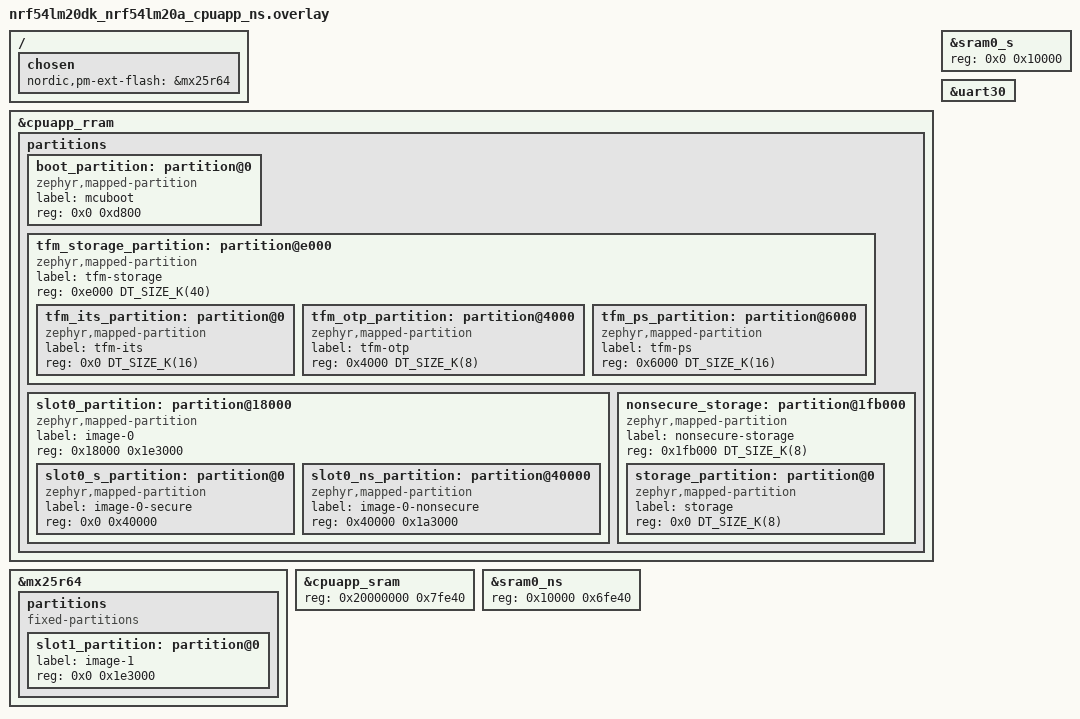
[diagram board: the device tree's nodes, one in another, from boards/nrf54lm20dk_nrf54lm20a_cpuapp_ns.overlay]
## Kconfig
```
#
# Copyright (c) 2022 Nordic Semiconductor ASA
#
# SPDX-License-Identifier: LicenseRef-Nordic-5-Clause
#

menu "Azure IoT Hub sample"

module = AZURE_IOT_HUB_SAMPLE
module-str = Azure IoT Hub sample
source "$(ZEPHYR_BASE)/subsys/logging/Kconfig.template.log_config"

config AZURE_IOT_HUB_SAMPLE_DEVICE_ID_USE_HW_ID
	bool "Use HW ID as device ID"
	select HW_ID_LIBRARY
	help
	  Use the devices's hardware ID as device ID when connecting to Azure IOT Hub

config AZURE_IOT_HUB_SAMPLE_CONNECTION_RETRY_TIMEOUT_SECONDS
	int "Number of seconds between each Azure IoT Hub connection retry"
	default 30
	help
	  If the connection fails, the sample tries to connect again at this interval,
	  or earlier if the network connectivity changes.

endmenu

menu "Zephyr Kernel"
source "Kconfig.zephyr"
endmenu
```

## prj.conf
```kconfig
#
# Copyright (c) 2020 Nordic Semiconductor ASA
#
# SPDX-License-Identifier: LicenseRef-Nordic-5-Clause
#

# General config
CONFIG_REBOOT=y
CONFIG_ASSERT=y

# Logging
CONFIG_LOG=y
CONFIG_LOG_MODE_DEFERRED=y

# Network
CONFIG_NETWORKING=y
CONFIG_NET_NATIVE=y
CONFIG_NET_IPV4=y
CONFIG_NET_CONNECTION_MANAGER=y

# Azure IoT Hub library
CONFIG_MQTT_HELPER_PROVISION_CERTIFICATES=y
CONFIG_AZURE_IOT_HUB=y
CONFIG_AZURE_IOT_HUB_DEVICE_ID="simon-home-nrf7002dk"
# Host name must be configured if DPS is not used
CONFIG_AZURE_IOT_HUB_HOSTNAME="testSthlm.azure-devices.net"
# Change the security tag to the tag where Azure IoT Hub certificates
# are provisioned
CONFIG_MQTT_HELPER_SEC_TAG=10
CONFIG_MQTT_HELPER_STACK_SIZE=8192

# Uncomment to get more verbose logging when debugging
# CONFIG_AZURE_IOT_HUB_LOG_LEVEL_DBG=y

# MQTT - Maximum MQTT keepalive timeout specified by Azure IoT Hub
CONFIG_MQTT_KEEPALIVE=1767

# cJSON
CONFIG_CJSON_LIB=y

# Settings, needed for Azure Device Provisioning Service
CONFIG_FLASH=y
CONFIG_FLASH_MAP=y
CONFIG_FCB=y
CONFIG_SETTINGS=y
CONFIG_SETTINGS_FCB=y
CONFIG_MPU_ALLOW_FLASH_WRITE=y
```

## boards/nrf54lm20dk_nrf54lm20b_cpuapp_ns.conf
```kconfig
#
# Copyright (c) 2026 Nordic Semiconductor ASA
#
# SPDX-License-Identifier: LicenseRef-Nordic-5-Clause
#

# General
CONFIG_POSIX_TIMERS=y
CONFIG_HW_ID_LIBRARY=y
CONFIG_HW_ID_LIBRARY_SOURCE_NET_MAC=y
CONFIG_DK_LIBRARY=y

# Heap and stacks
CONFIG_MAIN_STACK_SIZE=6144
CONFIG_SYSTEM_WORKQUEUE_STACK_SIZE=4096
CONFIG_HEAP_MEM_POOL_SIZE=40144
CONFIG_NRF_WIFI_CTRL_HEAP_SIZE=15000
CONFIG_NRF_WIFI_DATA_HEAP_SIZE=64856
CONFIG_HEAP_MEM_POOL_IGNORE_MIN=y
CONFIG_NET_RX_STACK_SIZE=2048

# Optimize Wi-Fi stack to save some memory
CONFIG_NRF70_RX_NUM_BUFS=16
CONFIG_NRF70_MAX_TX_AGGREGATION=4

# Wi-Fi
CONFIG_WIFI=y
CONFIG_WIFI_NRF70=y
CONFIG_WIFI_NRF70_LOG_LEVEL_ERR=y
CONFIG_WIFI_CREDENTIALS=y
CONFIG_FLASH_PAGE_LAYOUT=y
CONFIG_NET_L2_WIFI_SHELL=y

# Logging: default LOG_PROCESS stack is 768 B; with CONFIG_CBPRINTF_FP_SUPPORT that overflows
# easily and can corrupt state, TF-M secure fault INVEP on the next PSA/crypto call.
CONFIG_LOG_PROCESS_THREAD_STACK_SIZE=4096

# Shell
CONFIG_SHELL=y
CONFIG_SHELL_STACK_SIZE=6144

# WPA
CONFIG_WIFI_NM_WPA_SUPPLICANT=y
CONFIG_WIFI_NM_WPA_SUPPLICANT_LOG_LEVEL_ERR=y

# Zephyr NET Connection Manager Connectivity layer.
CONFIG_L2_WIFI_CONNECTIVITY=y
CONFIG_L2_WIFI_CONNECTIVITY_AUTO_CONNECT=n
CONFIG_L2_WIFI_CONNECTIVITY_AUTO_DOWN=n

# DNS
CONFIG_DNS_RESOLVER=y
CONFIG_NET_SOCKETS_DNS_TIMEOUT=30000

# NET sockets
CONFIG_NET_SOCKETS=y
CONFIG_NET_L2_ETHERNET=y
CONFIG_NET_TCP=y
CONFIG_NET_UDP=y
CONFIG_NET_SOCKETS_OFFLOAD=n
CONFIG_NET_DHCPV4=y
CONFIG_NET_CONTEXT_SNDTIMEO=y
CONFIG_NET_CONTEXT_RCVTIMEO=y

# TLS networking
CONFIG_NET_SOCKETS_SOCKOPT_TLS=y
CONFIG_NET_SOCKETS_ENABLE_DTLS=n
CONFIG_NET_SOCKETS_TLS_MAX_CONTEXTS=2

# mbedTLS
CONFIG_MBEDTLS=y
CONFIG_MBEDTLS_ENABLE_HEAP=y
CONFIG_MBEDTLS_HEAP_SIZE=81920
CONFIG_MBEDTLS_DECLARE_PRIVATE_IDENTIFIERS=y
CONFIG_MBEDTLS_MD_C=y
CONFIG_MBEDTLS_HMAC_DRBG_C=y
CONFIG_MBEDTLS_SHA256_C=y
CONFIG_MBEDTLS_ECP_C=y
CONFIG_MBEDTLS_CTR_DRBG_C=y
CONFIG_MBEDTLS_AES_C=y
CONFIG_MBEDTLS_ENTROPY_C=y
CONFIG_MBEDTLS_RSA_C=y
CONFIG_PSA_WANT_KEY_TYPE_RSA_KEY_PAIR_IMPORT=y
CONFIG_PSA_WANT_KEY_TYPE_RSA_KEY_PAIR_EXPORT=y
CONFIG_PSA_WANT_KEY_TYPE_RSA_KEY_PAIR_GENERATE=y
CONFIG_MBEDTLS_SSL_SERVER_NAME_INDICATION=y
# Set MPI (Multiple Precision Integer) size limit to 512 bytes for handling of 4 kb certificates
# in cryptographic operations.
CONFIG_MBEDTLS_MPI_MAX_SIZE=512
# ECDH/ECDSA are needed for TLS handshake
CONFIG_PSA_WANT_ALG_ECDH=y
CONFIG_PSA_WANT_ALG_ECDSA=y
# CRACEN auto-enables CHACHA20_POLY1305 and certain ECC algorithms. Clients
# pick these ciphers; psa_import_key then fails unless the matching key types
# and curves are explicitly declared here.
CONFIG_PSA_WANT_ECC_SECP_R1_256=y
CONFIG_PSA_WANT_ECC_SECP_R1_384=y
CONFIG_PSA_WANT_ALG_ECDSA_ANY=y
CONFIG_PSA_WANT_KEY_TYPE_CHACHA20=y

# TF-M PSA IPC scratch buffer; inputs+outputs of a single PSA call are copied through it.
# 36864 = 2 * MBEDTLS_SSL_MAX_CONTENT_LEN (16384) + overhead, covering the largest
# in/out buffers seen during the TLS handshake via CRACEN. Values below ~16384 cause
# psa_* calls to fail (ECONNABORTED) during the handshake.
#CONFIG_TFM_CRYPTO_IOVEC_BUFFER_SIZE=36864

# FOTA
CONFIG_AZURE_FOTA=y
CONFIG_AZURE_FOTA_APP_VERSION_AUTO=n
CONFIG_AZURE_FOTA_TLS=y
# Change the security tag to the tag where the certificates are provisioned
# for the server where the FOTA image is hosted
CONFIG_AZURE_FOTA_SEC_TAG=11
CONFIG_BOOTLOADER_MCUBOOT=y
CONFIG_FOTA_DOWNLOAD=y
CONFIG_DFU_TARGET=y
# Not compatible with TF-M NS RAM layout (sysbuild clears this for NS anyway).
CONFIG_MCUBOOT_USE_ALL_AVAILABLE_RAM=n
CONFIG_MCUBOOT_IMG_MANAGER=y
CONFIG_IMG_MANAGER=y
CONFIG_STREAM_FLASH=y
CONFIG_IMG_ERASE_PROGRESSIVELY=y
CONFIG_DOWNLOADER=y
CONFIG_DOWNLOADER_STACK_SIZE=4096

# Enable external flash to host MCUBoot secondary partition
CONFIG_SPI=y
CONFIG_SPI_NOR=y
CONFIG_SPI_NOR_SFDP_DEVICETREE=y

# TLS credentials
CONFIG_TLS_CREDENTIALS_BACKEND_PROTECTED_STORAGE=y

# Configure TF-M
CONFIG_TFM_PROFILE_TYPE_NOT_SET=y
# TF-M and nRF7002EB2 shield use the same UART30. TF-M assigns UART30 to secure environment, which
# causes BusFault when app tries to access it. Disabling logging in TF-M prevent it using UART30.
CONFIG_TFM_LOG_LEVEL_SILENCE=y

# Enable LTO to save flash memory
CONFIG_LTO=y
CONFIG_ISR_TABLES_LOCAL_DECLARATION=y

# Floating-point printf support
CONFIG_CBPRINTF_FP_SUPPORT=y
```

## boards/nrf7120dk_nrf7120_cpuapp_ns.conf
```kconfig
#
# Copyright (c) 2026 Nordic Semiconductor ASA
#
# SPDX-License-Identifier: LicenseRef-Nordic-5-Clause
#

# General
CONFIG_POSIX_TIMERS=y
CONFIG_HW_ID_LIBRARY=y
CONFIG_HW_ID_LIBRARY_SOURCE_NET_MAC=y
CONFIG_DK_LIBRARY=y

# Wi-Fi
CONFIG_WIFI=y
CONFIG_WIFI_NRF71=y
CONFIG_WIFI_CREDENTIALS=y
# Needed for Wi-Fi credentials
CONFIG_FLASH=y
CONFIG_FLASH_PAGE_LAYOUT=y
CONFIG_ZMS=y
CONFIG_SETTINGS=y

# Shell
CONFIG_SHELL=y
CONFIG_SHELL_STACK_SIZE=6144
CONFIG_NET_L2_WIFI_SHELL=y

# WPA
CONFIG_WIFI_NM_WPA_SUPPLICANT=y
CONFIG_WIFI_NM_WPA_SUPPLICANT_LOG_LEVEL_ERR=y

# Zephyr NET Connection Manager Connectivity layer.
CONFIG_L2_WIFI_CONNECTIVITY=y
CONFIG_L2_WIFI_CONNECTIVITY_AUTO_CONNECT=n
CONFIG_L2_WIFI_CONNECTIVITY_AUTO_DOWN=n

# DNS
CONFIG_DNS_RESOLVER=y
CONFIG_NET_SOCKETS_DNS_TIMEOUT=30000

# NET sockets
CONFIG_NET_SOCKETS=y
CONFIG_NET_L2_ETHERNET=y
CONFIG_NET_TCP=y
CONFIG_NET_UDP=y
CONFIG_NET_SOCKETS_OFFLOAD=n
CONFIG_NET_DHCPV4=y
CONFIG_NET_CONTEXT_SNDTIMEO=y
CONFIG_NET_CONTEXT_RCVTIMEO=y

# TLS networking
CONFIG_NET_SOCKETS_SOCKOPT_TLS=y
CONFIG_NET_SOCKETS_ENABLE_DTLS=n
CONFIG_NET_SOCKETS_TLS_MAX_CONTEXTS=2

# mbedTLS
CONFIG_MBEDTLS=y
CONFIG_MBEDTLS_ENABLE_HEAP=y
CONFIG_MBEDTLS_HEAP_SIZE=81920
CONFIG_MBEDTLS_DECLARE_PRIVATE_IDENTIFIERS=y
CONFIG_MBEDTLS_MD_C=y
CONFIG_MBEDTLS_HMAC_DRBG_C=y
CONFIG_MBEDTLS_SHA256_C=y
CONFIG_MBEDTLS_ECP_C=y
CONFIG_MBEDTLS_CTR_DRBG_C=y
CONFIG_MBEDTLS_AES_C=y
CONFIG_MBEDTLS_ENTROPY_C=y
CONFIG_MBEDTLS_RSA_C=y
CONFIG_PSA_WANT_KEY_TYPE_RSA_KEY_PAIR_IMPORT=y
CONFIG_PSA_WANT_KEY_TYPE_RSA_KEY_PAIR_EXPORT=y
CONFIG_PSA_WANT_KEY_TYPE_RSA_KEY_PAIR_GENERATE=y
CONFIG_MBEDTLS_SSL_SERVER_NAME_INDICATION=y
# Set MPI (Multiple Precision Integer) size limit to 512 bytes for handling of 4 kb certificates
# in cryptographic operations.
CONFIG_MBEDTLS_MPI_MAX_SIZE=512
# ECDH/ECDSA are needed for TLS handshake
CONFIG_PSA_WANT_ALG_ECDH=y
CONFIG_PSA_WANT_ALG_ECDSA=y

# HOSTAP_CRYPTO_ALT_PSA (default) force-selects MBEDTLS_USE_PSA_CRYPTO, which
# routes mbedTLS TLS/X.509 operations through PSA via TF-M IPC. This currently
# fails with MBEDTLS_ERR_SSL_HW_ACCEL_FAILED during the TLS handshake on TF-M
# NS builds. The legacy PSA backend does not force MBEDTLS_USE_PSA_CRYPTO, so
# mbedTLS uses its built-in crypto for TLS while WPA supplicant still uses PSA.
CONFIG_HOSTAP_CRYPTO_ALT_LEGACY_PSA=y

# FOTA
CONFIG_AZURE_FOTA=y
CONFIG_AZURE_FOTA_APP_VERSION_AUTO=n
CONFIG_AZURE_FOTA_TLS=y
# Change the security tag to the tag where the certificates are provisioned
# for the server where the FOTA image is hosted
CONFIG_AZURE_FOTA_SEC_TAG=11
CONFIG_BOOTLOADER_MCUBOOT=y
CONFIG_FOTA_DOWNLOAD=y
CONFIG_DFU_TARGET=y

# TLS credentials
CONFIG_TLS_CREDENTIALS_BACKEND_PROTECTED_STORAGE=y

# Enable LTO to save flash memory
CONFIG_LTO=y
CONFIG_ISR_TABLES_LOCAL_DECLARATION=y

# Floating-point printf support
CONFIG_CBPRINTF_FP_SUPPORT=y

# Optimize Wi-Fi stack to save some memory
CONFIG_HEAP_MEM_POOL_SIZE=40144
CONFIG_NRF_WIFI_CTRL_HEAP_SIZE=20000
CONFIG_NRF_WIFI_DATA_HEAP_SIZE=59856
```

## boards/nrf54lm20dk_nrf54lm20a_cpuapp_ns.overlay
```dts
/*
 * Copyright (c) 2026 Nordic Semiconductor ASA
 *
 * SPDX-License-Identifier: LicenseRef-Nordic-5-Clause
 */

/ {
	/* Configure partition manager to use mx25r64 as the external flash */
	chosen {
		nordic,pm-ext-flash = &mx25r64;
	};
};

/delete-node/ &slot0_s_partition;
/delete-node/ &tfm_ps_partition;
/delete-node/ &tfm_its_partition;
/delete-node/ &tfm_otp_partition;
/delete-node/ &slot0_ns_partition;
/delete-node/ &storage_partition;

&cpuapp_rram {
	partitions {
		boot_partition: partition@0 {
			compatible = "zephyr,mapped-partition";
			label = "mcuboot";
			reg = <0x0 0xd800>;
		};

		tfm_storage_partition: partition@e000 {
			compatible = "zephyr,mapped-partition";
			label = "tfm-storage";
			reg = <0xe000 DT_SIZE_K(40)>;
			ranges = <0x0 0xe000 DT_SIZE_K(40)>;
			#address-cells = <1>;
			#size-cells = <1>;

			tfm_its_partition: partition@0 {
				compatible = "zephyr,mapped-partition";
				label = "tfm-its";
				reg = <0x0 DT_SIZE_K(16)>;
			};

			tfm_otp_partition: partition@4000 {
				compatible = "zephyr,mapped-partition";
				label = "tfm-otp";
				reg = <0x4000 DT_SIZE_K(8)>;
			};

			tfm_ps_partition: partition@6000 {
				compatible = "zephyr,mapped-partition";
				label = "tfm-ps";
				reg = <0x6000 DT_SIZE_K(16)>;
			};
		};

		slot0_partition: partition@18000 {
			compatible = "zephyr,mapped-partition";
			label = "image-0";
			reg = <0x18000 0x1e3000>;
			ranges = <0x0 0x18000 0x1e3000>;
			#address-cells = <1>;
			#size-cells = <1>;

			slot0_s_partition: partition@0 {
				compatible = "zephyr,mapped-partition";
				label = "image-0-secure";
				reg = <0x0 0x40000>;
			};

			slot0_ns_partition: partition@40000 {
				compatible = "zephyr,mapped-partition";
				label = "image-0-nonsecure";
				reg = <0x40000 0x1a3000>;
			};
		};

		nonsecure_storage: partition@1fb000 {
			compatible = "zephyr,mapped-partition";
			label = "nonsecure-storage";
			reg = <0x1fb000 DT_SIZE_K(8)>;
			ranges = <0x0 0x1fb000 DT_SIZE_K(8)>;
			#address-cells = <1>;
			#size-cells = <1>;

			storage_partition: partition@0 {
				compatible = "zephyr,mapped-partition";
				label = "storage";
				reg = <0x0 DT_SIZE_K(8)>;
			};
		};
	};
};

&mx25r64 {
	status = "okay";

	partitions {
		compatible = "fixed-partitions";
		#address-cells = <1>;
		#size-cells = <1>;

		slot1_partition: partition@0 {
			label = "image-1";
			reg = <0x0 0x1e3000>;
		};
	};
};

/*
 * CPUAPP SRAM TrustZone split: TF-M uses the first 64 KiB (&sram0_s, reg 0x10000); the NS
 * workload uses the remainder (&sram0_ns). These sizes must match the TF-M platform RAM
 * layout for nRF54LM20.
 */
&cpuapp_sram {
	reg = <0x20000000 0x7fe40>;
	ranges = <0x0 0x20000000 0x7fe40>;
};

&sram0_s {
	reg = <0x0 0x10000>;
	ranges = <0x0 0x0 0x10000>;
};

&sram0_ns {
	reg = <0x10000 0x6fe40>;
	ranges = <0x0 0x10000 0x6fe40>;
};

/*
 * Board NS DTS keeps &uart30 disabled for the default TF-M UARTE30 logging case.
 * With CONFIG_TFM_LOG_LEVEL_SILENCE=y TF-M does not use that UART; re-enable UARTE30 for NS.
 */
&uart30 {
	status = "okay";
};
```

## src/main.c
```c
/*
 * Copyright (c) 2020-2023 Nordic Semiconductor ASA
 *
 * SPDX-License-Identifier: LicenseRef-Nordic-5-Clause
 */


#include <stdio.h>
#include <stdlib.h>
#include <zephyr/kernel.h>
#include <zephyr/sys/reboot.h>
#include <zephyr/net/conn_mgr_connectivity.h>
#include <zephyr/net/conn_mgr_monitor.h>
#include <zephyr/dfu/mcuboot.h>
#include <net/azure_iot_hub.h>
#include <net/azure_iot_hub_dps.h>
#include <zephyr/logging/log.h>

#include <dk_buttons_and_leds.h>
#include <cJSON.h>
#include <cJSON_os.h>

#include <hw_id.h>

#ifndef CONFIG_AZURE_IOT_HUB_DPS_TIMEOUT_SEC
#define CONFIG_AZURE_IOT_HUB_DPS_TIMEOUT_SEC 0
#endif

LOG_MODULE_REGISTER(azure_iot_hub_sample, CONFIG_AZURE_IOT_HUB_SAMPLE_LOG_LEVEL);

/* Macros used to subscribe to specific Zephyr net management events. */
#define L4_EVENT_MASK (NET_EVENT_L4_CONNECTED | NET_EVENT_L4_DISCONNECTED)
#define CONN_LAYER_EVENT_MASK (NET_EVENT_CONN_IF_FATAL_ERROR)

/* Any IP family, and DNS to resolve the host names */
#define READY_MASK (CONN_MGR_READY_IPV4 | CONN_MGR_READY_IPV6 | CONN_MGR_READY_DNS)

/* Interval [s] between sending events to the IoT hub. The value can be changed
 * by setting a new desired value for property 'telemetryInterval' in the
 * device twin document.
 */
#define EVENT_INTERVAL		20
#define RECV_BUF_SIZE		1024
#define APP_WORK_Q_STACK_SIZE	KB(8)

static struct method_data {
	struct k_work work;
	char request_id[8];
	char name[32];
	char payload[200];
} method_data;
static struct k_work twin_report_work;
static struct k_work_delayable send_event_work;
static struct k_work_delayable reboot_work;

static char recv_buf[RECV_BUF_SIZE];
static void direct_method_handler(struct k_work *work);
static K_SEM_DEFINE(network_connected_sem, 0, 1);
static K_SEM_DEFINE(recv_buf_sem, 1, 1);
static atomic_t event_interval = EVENT_INTERVAL;

static bool dps_was_successful;

/* A work queue is created to execute potentially blocking calls from.
 * This is done to avoid blocking for example the system work queue for extended
 * periods of time.
 */
static K_THREAD_STACK_DEFINE(application_stack_area, APP_WORK_Q_STACK_SIZE);
static struct k_work_q application_work_q;

/* Returns a positive integer if the new interval can be parsed, otherwise -1 */
static int event_interval_get(char *buf)
{
	struct cJSON *root_obj, *desired_obj, *event_interval_obj;
	int new_interval = -1;

	root_obj = cJSON_Parse(buf);
	if (root_obj == NULL) {
		LOG_ERR("Could not parse properties object");
		return -1;
	}

	/* If the incoming buffer is a notification from the cloud about changes
	 * made to the device twin's "desired" properties, the root object will
	 * only contain the newly changed properties, and can be treated as if
	 * it is the "desired" object.
	 * If the incoming is the response to a request to receive the device
	 * twin, it will contain a "desired" object and a "reported" object,
	 * and we need to access that object instead of the root.
	 */
	desired_obj = cJSON_GetObjectItem(root_obj, "desired");
	if (desired_obj == NULL) {
		LOG_DBG("Incoming device twin document contains only the 'desired' object");

		desired_obj = root_obj;
	}

	/* Update only recognized properties. */
	event_interval_obj = cJSON_GetObjectItem(desired_obj,
						 "telemetryInterval");
	if (event_interval_obj == NULL) {
		LOG_DBG("No 'telemetryInterval' object found in the device twin document");

		goto clean_exit;
	}

	if (cJSON_IsString(event_interval_obj)) {
		new_interval = atoi(event_interval_obj->valuestring);
	} else if (cJSON_IsNumber(event_interval_obj)) {
		new_interval = event_interval_obj->valueint;
	} else {
		LOG_WRN("Invalid telemetry interval format received");
		goto clean_exit;
	}

clean_exit:
	cJSON_Delete(root_obj);
	k_sem_give(&recv_buf_sem);

	return new_interval;
}

static void event_interval_apply(int interval)
{
	if (interval <= 0) {
		return;
	}

	atomic_set(&event_interval, interval);
	k_work_reschedule_for_queue(&application_work_q, &send_event_work, K_NO_WAIT);
}

static void on_evt_twin_desired(char *buf, size_t len)
{
	if (k_sem_take(&recv_buf_sem, K_NO_WAIT) == 0) {
		if (len > sizeof(recv_buf) - 1) {
			LOG_ERR("Incoming data too big for buffer");
			return;
		}

		memcpy(recv_buf, buf, len);
		recv_buf[len] = '\0';
		k_work_submit_to_queue(&application_work_q, &twin_report_work);
	} else {
		LOG_WRN("Recv buffer is busy, data was not copied");
	}
}

static void on_evt_direct_method(struct azure_iot_hub_method *method)
{
	size_t request_id_len = MIN(sizeof(method_data.request_id) - 1, method->request_id.size);
	size_t name_len = MIN(sizeof(method_data.name) - 1, method->name.size);

	LOG_INF("Method name: %.*s", method->name.size, method->name.ptr);
	LOG_INF("Payload: %.*s", method->payload.size, method->payload.ptr);

	memcpy(method_data.request_id, method->request_id.ptr, request_id_len);

	method_data.request_id[request_id_len] = '\0';

	memcpy(method_data.name, method->name.ptr, name_len);
	method_data.name[name_len] = '\0';

	snprintk(method_data.payload, sizeof(method_data.payload),
		 "%.*s", method->payload.size, method->payload.ptr);

	k_work_submit_to_queue(&application_work_q, &method_data.work);
}

static void reboot_work_fn(struct k_work *work)
{
	ARG_UNUSED(work);

	sys_reboot(SYS_REBOOT_COLD);
}

static void azure_event_handler(struct azure_iot_hub_evt *const evt)
{
	switch (evt->type) {
	case AZURE_IOT_HUB_EVT_CONNECTING:
		LOG_INF("AZURE_IOT_HUB_EVT_CONNECTING");
		break;
	case AZURE_IOT_HUB_EVT_CONNECTED:
		LOG_INF("AZURE_IOT_HUB_EVT_CONNECTED");
		break;
	case AZURE_IOT_HUB_EVT_CONNECTION_FAILED:
		LOG_INF("AZURE_IOT_HUB_EVT_CONNECTION_FAILED");
		LOG_INF("Error code received from IoT Hub: %d",
			evt->data.err);
		break;
	case AZURE_IOT_HUB_EVT_DISCONNECTED:
		LOG_INF("AZURE_IOT_HUB_EVT_DISCONNECTED");
		break;
	case AZURE_IOT_HUB_EVT_READY:
		LOG_INF("AZURE_IOT_HUB_EVT_READY");

		/* All initializations and cloud connection were successful, now mark
		 * image as working so that we will not revert upon reboot.
		 */
		if (IS_ENABLED(CONFIG_BOOTLOADER_MCUBOOT)) {
			boot_write_img_confirmed();
		}

		/* The AZURE_IOT_HUB_EVT_READY event indicates that the
		 * IoT hub connection is established and interaction with the
		 * cloud can begin.
		 *
		 * The below work submission will cause send_event() to be
		 * call after 3 seconds.
		 */
		k_work_reschedule_for_queue(&application_work_q,
					    &send_event_work, K_NO_WAIT);
		break;
	case AZURE_IOT_HUB_EVT_DATA_RECEIVED:
		LOG_INF("AZURE_IOT_HUB_EVT_DATA_RECEIVED");
		LOG_INF("Received payload: %.*s",
			evt->data.msg.payload.size, evt->data.msg.payload.ptr);
		break;
	case AZURE_IOT_HUB_EVT_TWIN_RECEIVED:
		LOG_INF("AZURE_IOT_HUB_EVT_TWIN_RECEIVED");
		event_interval_apply(event_interval_get(evt->data.msg.payload.ptr));
		break;
	case AZURE_IOT_HUB_EVT_TWIN_DESIRED_RECEIVED:
		LOG_INF("AZURE_IOT_HUB_EVT_TWIN_DESIRED_RECEIVED");
		on_evt_twin_desired(evt->data.msg.payload.ptr, evt->data.msg.payload.size);
		break;
	case AZURE_IOT_HUB_EVT_DIRECT_METHOD:
		LOG_INF("AZURE_IOT_HUB_EVT_DIRECT_METHOD");
		on_evt_direct_method(&evt->data.method);
		break;
	case AZURE_IOT_HUB_EVT_TWIN_RESULT_SUCCESS:
		LOG_INF("AZURE_IOT_HUB_EVT_TWIN_RESULT_SUCCESS, ID: %.*s",
			evt->data.result.request_id.size, evt->data.result.request_id.ptr);
		break;
	case AZURE_IOT_HUB_EVT_TWIN_RESULT_FAIL:
		LOG_INF("AZURE_IOT_HUB_EVT_TWIN_RESULT_FAIL, ID %.*s, status %d",
			evt->data.result.request_id.size,
			evt->data.result.request_id.ptr,
			evt->data.result.status);
		break;
	case AZURE_IOT_HUB_EVT_PUBACK:
		LOG_INF("AZURE_IOT_HUB_EVT_PUBACK");
		break;
	case AZURE_IOT_HUB_EVT_FOTA_START:
		LOG_INF("AZURE_IOT_HUB_EVT_FOTA_START");
		break;
	case AZURE_IOT_HUB_EVT_FOTA_DONE:
		LOG_INF("AZURE_IOT_HUB_EVT_FOTA_DONE");
		LOG_INF("The device will reboot in 5 seconds to apply update");
		k_work_schedule(&reboot_work, K_SECONDS(5));
		break;
	case AZURE_IOT_HUB_EVT_FOTA_ERASE_PENDING:
		LOG_INF("AZURE_IOT_HUB_EVT_FOTA_ERASE_PENDING");
		break;
	case AZURE_IOT_HUB_EVT_FOTA_ERASE_DONE:
		LOG_INF("AZURE_IOT_HUB_EVT_FOTA_ERASE_DONE");
		break;
	case AZURE_IOT_HUB_EVT_FOTA_ERROR:
		LOG_ERR("AZURE_IOT_HUB_EVT_FOTA_ERROR: FOTA failed");
		break;
	case AZURE_IOT_HUB_EVT_ERROR:
		LOG_INF("AZURE_IOT_HUB_EVT_ERROR");
		break;
	default:
		LOG_ERR("Unknown Azure IoT Hub event type: %d", evt->type);
		break;
	}
}

static void send_event(struct k_work *work)
{
	int err;
	static char buf[60];
	ssize_t len;
	struct azure_iot_hub_msg msg = {
		.topic.type = AZURE_IOT_HUB_TOPIC_EVENT,
		.payload.ptr = buf,
		.qos = MQTT_QOS_0_AT_MOST_ONCE,
	};

	len = snprintk(buf, sizeof(buf),
		       "{\"temperature\":%d.%d,\"timestamp\":%d}",
		       25, k_uptime_get_32() % 10, k_uptime_get_32());
	if ((len < 0) || (len > sizeof(buf))) {
		LOG_ERR("Failed to populate event buffer");
		goto exit;
	}

	msg.payload.size = len;

	LOG_INF("Sending event:%s", buf);

	err = azure_iot_hub_send(&msg);
	if (err) {
		LOG_ERR("Failed to send event");
		goto exit;
	}

	LOG_INF("Event was successfully sent");
exit:
	if (atomic_get(&event_interval) <= 0) {
		LOG_ERR("The event reporting stops, interval is set to %ld",
		       atomic_get(&event_interval));
		return;
	}

	LOG_INF("Next event will be sent in %ld seconds", event_interval);
	k_work_reschedule_for_queue(&application_work_q, &send_event_work,
				    K_SECONDS(event_interval));
}

static void direct_method_handler(struct k_work *work)
{
	int err;
	static const char response[] = "{\"it\":\"worked\"}";

	/* Status code 200 indicates successful execution of direct method. */
	struct azure_iot_hub_result result = {
		.request_id = {
			.ptr = method_data.request_id,
			.size = strlen(method_data.request_id),
		},
		.status = 200,
		.payload.ptr = (char *)response,
		.payload.size = sizeof(response) - 1,
	};
	bool led_state = strncmp(method_data.payload, "0", 1) ? 1 : 0;

	if (strcmp(method_data.name, "led") != 0) {
		LOG_INF("Unknown direct method");
		return;
	}

	if (IS_ENABLED(CONFIG_DK_LIBRARY)) {
		err = dk_set_led(DK_LED1, led_state);
		if (err) {
			LOG_ERR("Failed to set LED, error: %d", err);
			return;
		}
	} else {
		LOG_INF("No hardware interface to set LED state to %d", led_state);
	}

	err = azure_iot_hub_method_respond(&result);
	if (err) {
		LOG_ERR("Failed to send direct method response");
	}
}

static void twin_report_work_fn(struct k_work *work)
{
	int err;
	char buf[100];
	ssize_t len;
	struct azure_iot_hub_msg data = {
		.topic.type = AZURE_IOT_HUB_TOPIC_TWIN_REPORTED,
		.payload.ptr = buf,
		.qos = MQTT_QOS_0_AT_MOST_ONCE,
	};
	int new_interval;

	new_interval = event_interval_get(recv_buf);
	if (new_interval < 0) {
		return;
	}

	len = snprintk(buf, sizeof(buf),
		       "{\"telemetryInterval\":%d}", new_interval);
	if (len <= 0) {
		LOG_ERR("Failed to create twin report");
		return;
	}

	data.payload.size = len;

	err = azure_iot_hub_send(&data);
	if (err) {
		LOG_ERR("Failed to send twin report");
		return;
	}

	/* Note that the new interval value is first applied here, because that
	 * will make the "reported" value in the device twin be in sync with
	 * the reality on the device. Other applications may decide
	 * to apply the desired properties regardless of whether the value is
	 * successfully reported or not.
	 */
	event_interval_apply(new_interval);
	LOG_INF("New telemetry interval has been applied: %d",  new_interval);
}

static void on_net_event_l4_connected(void)
{
	k_sem_give(&network_connected_sem);
}

static void on_net_event_l4_disconnected(void)
{
	(void)azure_iot_hub_disconnect();
}



static void l4_event_handler(uint64_t event, struct net_if *iface, void *info,
			     size_t info_length, void *user_data)
{
	switch (event) {
	case NET_EVENT_L4_CONNECTED:
		LOG_INF("Network connectivity established and IP address assigned");
		on_net_event_l4_connected();
		break;
	case NET_EVENT_L4_DISCONNECTED:
		LOG_INF("Network connectivity lost, no IP address assigned");
		on_net_event_l4_disconnected();
		break;
	default:
		return;
	}
}

static void connectivity_event_handler(uint64_t event, struct net_if *iface, void *info,
				       size_t info_length, void *user_data)
{
	if (event == NET_EVENT_CONN_IF_FATAL_ERROR) {
		LOG_ERR("Fatal error received from the connectivity layer, rebooting");
		sys_reboot(SYS_REBOOT_COLD);
		CODE_UNREACHABLE;
	}
}

/* Registered statically to not miss events raised before main() */
NET_MGMT_REGISTER_EVENT_HANDLER(l4_events, L4_EVENT_MASK, l4_event_handler, NULL);
NET_MGMT_REGISTER_EVENT_HANDLER(conn_events, CONN_LAYER_EVENT_MASK, connectivity_event_handler,
				NULL);

static void work_init(void)
{
	const struct k_work_queue_config cfg = {
		.name = "application_work_q",
	};

	k_work_init(&method_data.work, direct_method_handler);
	k_work_init(&twin_report_work, twin_report_work_fn);
	k_work_init_delayable(&send_event_work, send_event);
	k_work_init_delayable(&reboot_work, reboot_work_fn);

	k_work_queue_start(&application_work_q, application_stack_area,
		       K_THREAD_STACK_SIZEOF(application_stack_area),
		       K_HIGHEST_APPLICATION_THREAD_PRIO, &cfg);
}

static K_SEM_DEFINE(dps_done_sem, 0, 1);

static void dps_handler(enum azure_iot_hub_dps_reg_status status)
{
	switch (status) {
	case AZURE_IOT_HUB_DPS_REG_STATUS_NOT_STARTED:
		LOG_INF("DPS registration status: AZURE_IOT_HUB_DPS_REG_STATUS_NOT_STARTED");
		break;
	case AZURE_IOT_HUB_DPS_REG_STATUS_ASSIGNING:
		LOG_INF("DPS registration status: AZURE_IOT_HUB_DPS_REG_STATUS_ASSIGNING");
		break;
	case AZURE_IOT_HUB_DPS_REG_STATUS_ASSIGNED:
		LOG_INF("DPS registration status: AZURE_IOT_HUB_DPS_REG_STATUS_ASSIGNED");

		dps_was_successful = true;

		k_sem_give(&dps_done_sem);
		break;
	case AZURE_IOT_HUB_DPS_REG_STATUS_FAILED:
		LOG_INF("DPS registration status: AZURE_IOT_HUB_DPS_REG_STATUS_FAILED");

		dps_was_successful = false;

		k_sem_give(&dps_done_sem);
		break;
	default:
		LOG_WRN("Unhandled DPS status: %d", status);
		break;
	}
}

/* Run DPS using the provided device_id as registration ID. Upon success, the function will return
 * 0 and populate the hostname and device_id buffers with the assigned values.
 * The return value will be a negative integer in case of failure.
 */
static int dps_run(struct azure_iot_hub_buf *hostname, struct azure_iot_hub_buf *device_id)
{
	int err;
	struct azure_iot_hub_dps_config dps_cfg = {
		.handler = dps_handler,
		.reg_id = {
			.ptr = device_id->ptr,
			.size = strlen(device_id->ptr),
		},
		/* Default ID scope provided by Kconfig is used, so we will not change that. */
	};

	LOG_INF("Starting DPS");

	err = azure_iot_hub_dps_init(&dps_cfg);
	if (err) {
		LOG_ERR("azure_iot_hub_dps_init failed, error: %d", err);
		return err;
	}

	err = azure_iot_hub_dps_start();
	if (err == 0) {
		LOG_INF("The DPS process has started, timeout is set to %d seconds",
			CONFIG_AZURE_IOT_HUB_DPS_TIMEOUT_SEC);

		/* If DPS was started successfully, we wait for the semaphore that is given when the
		 * provisioning completes.
		 */

		(void)k_sem_take(&dps_done_sem, K_FOREVER);

		if (!dps_was_successful) {
			return -EFAULT;
		}

		/* The device was assigned, continue to retrieve the hostname. */
	} else if (err == -EALREADY) {
		LOG_INF("Already assigned to an IoT hub, skipping DPS");
	} else {
		LOG_ERR("DPS failed to start, error: %d", err);
		return err;
	}

	err = azure_iot_hub_dps_hostname_get(hostname);
	if (err) {
		LOG_ERR("Failed to get hostname, error: %d", err);
		return err;
	}

	err = azure_iot_hub_dps_device_id_get(device_id);
	if (err) {
		LOG_ERR("Failed to get device ID, error: %d", err);
		return err;
	}

	LOG_INF("Device ID \"%.*s\" assigned to IoT hub with hostname \"%.*s\"",
		device_id->size, device_id->ptr,
		hostname->size, hostname->ptr);

	return 0;
}

static int iot_hub_connect(struct azure_iot_hub_config *cfg)
{
	int err;

	if (IS_ENABLED(CONFIG_AZURE_IOT_HUB_DPS)) {
		/* Using the device ID as DPS registration ID. */
		err = dps_run(&cfg->hostname, &cfg->device_id);
		if (err) {
			LOG_ERR("Failed to run DPS, error: %d", err);
			return err;
		}
	}

	err = azure_iot_hub_init(azure_event_handler);
	if (err) {
		LOG_ERR("Azure IoT Hub could not be initialized, error: %d", err);
		return err;
	}

	LOG_INF("Azure IoT Hub library initialized");

	err = azure_iot_hub_connect(cfg);
	if (err < 0) {
		LOG_ERR("azure_iot_hub_connect failed: %d", err);
		return err;
	}

	return 0;
}

int main(void)
{
	int err;
	uint32_t gen;
	static char hostname[128] = CONFIG_AZURE_IOT_HUB_HOSTNAME;
	static char device_id[128] = CONFIG_AZURE_IOT_HUB_DEVICE_ID;
	static struct azure_iot_hub_config cfg = {
		.device_id = {
			.ptr = device_id,
		},
		.hostname = {
			.ptr = hostname,
		},
		.use_dps = true,
	};

	cfg.device_id.size = strlen(device_id);
	cfg.hostname.size = strlen(hostname);


	LOG_INF("Azure IoT Hub sample started");

	LOG_INF("Bringing network interface up and connecting to the network");

	/* Connecting to the configured connectivity layer.
	 * Wi-Fi or LTE depending on the board that the sample was built for.
	 */
	err = conn_mgr_all_if_up(true);
	if (err) {
		LOG_ERR("conn_mgr_if_connect, error: %d", err);
		return err;
	}

	err = conn_mgr_all_if_connect(true);
	if (err) {
		LOG_ERR("conn_mgr_all_if_connect, error: %d", err);
		return err;
	}

	if (IS_ENABLED(CONFIG_AZURE_IOT_HUB_SAMPLE_DEVICE_ID_USE_HW_ID)) {
		err = hw_id_get(device_id, ARRAY_SIZE(device_id));
		if (err) {
			LOG_ERR("Failed to retrieve device ID");
			return 0;
		}
		cfg.device_id.size = strlen(device_id);
	}

	LOG_INF("Device ID: %s", device_id);

	if (!IS_ENABLED(CONFIG_AZURE_IOT_HUB_DPS)) {
		LOG_INF("Host name: %s", hostname);
	}

	if (IS_ENABLED(CONFIG_DK_LIBRARY)) {
		dk_leds_init();
	}

	work_init();
	cJSON_Init();

	k_sem_take(&network_connected_sem, K_FOREVER);

	LOG_INF("Connected to network");

	/* Retry on failure, early if the network changes meanwhile */
	while (true) {
		(void)conn_mgr_get_readiness(&gen);

		err = iot_hub_connect(&cfg);
		if (err == 0) {
			break;
		}

		LOG_INF("Next connection retry in %d seconds",
			CONFIG_AZURE_IOT_HUB_SAMPLE_CONNECTION_RETRY_TIMEOUT_SECONDS);
		(void)conn_mgr_wait_ready_change(READY_MASK, gen,
				K_SECONDS(CONFIG_AZURE_IOT_HUB_SAMPLE_CONNECTION_RETRY_TIMEOUT_SECONDS));
	}

	LOG_INF("Connection request sent to IoT Hub");

	/* After the connection to the IoT hub has been established, the
	 * Azure IoT Hub library will generate events when data is received.
	 * See azure_event_handler() for which actions will be taken on the
	 * various events.
	 */
	return 0;
}
```
